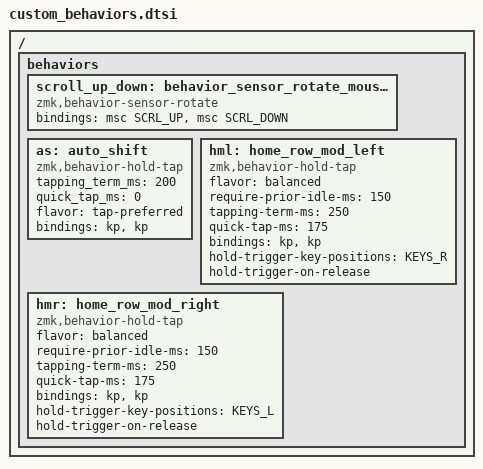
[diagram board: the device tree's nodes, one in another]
#include <dt-bindings/zmk/keys.h>
#include <behaviors.dtsi>
#include "custom_behaviors.h"

#define AS(keycode) &as LS(keycode) keycode     // Autoshift Macro
#define HML(MOD, TAP) &hml MOD TAP
#define HMR(MOD, TAP) &hmr MOD TAP

/ {
    behaviors {
        scroll_up_down: behavior_sensor_rotate_mouse_wheel_up_down {
            compatible = "zmk,behavior-sensor-rotate";
            #sensor-binding-cells = <0>;
            bindings = <&msc SCRL_UP>, <&msc SCRL_DOWN>;
        };
        as: auto_shift {
            compatible = "zmk,behavior-hold-tap";
            #binding-cells = <2>;
            tapping_term_ms = <200>;
            quick_tap_ms = <0>;
            flavor = "tap-preferred";
            bindings = <&kp>, <&kp>;
        };
        hml: home_row_mod_left {
            compatible = "zmk,behavior-hold-tap";
            #binding-cells = <2>;
            flavor = "balanced";
            require-prior-idle-ms = <150>;
            tapping-term-ms = <250>;
            quick-tap-ms = <175>;
            bindings = <&kp>, <&kp>;
            hold-trigger-key-positions = < KEYS_R >;
            hold-trigger-on-release;
        };
        hmr: home_row_mod_right {
            compatible = "zmk,behavior-hold-tap";
            #binding-cells = <2>;
            flavor = "balanced";
            require-prior-idle-ms = <150>;
            tapping-term-ms = <250>;
            quick-tap-ms = <175>;
            bindings = <&kp>, <&kp>;
            hold-trigger-key-positions = < KEYS_L >;
            hold-trigger-on-release;
        };
    };
};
